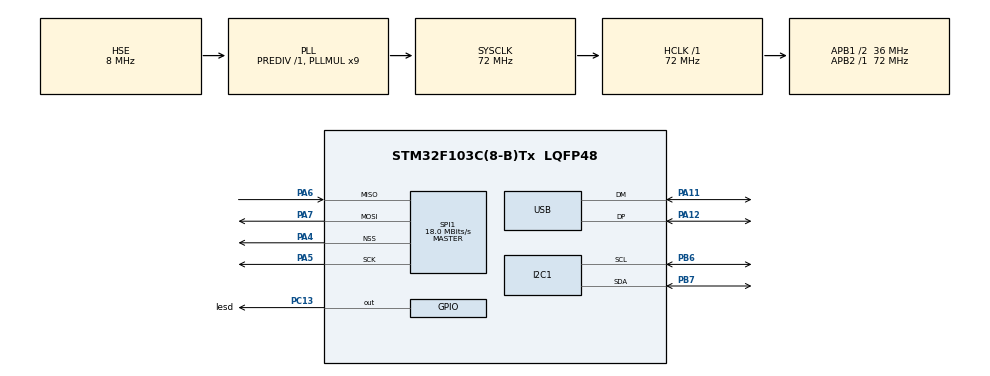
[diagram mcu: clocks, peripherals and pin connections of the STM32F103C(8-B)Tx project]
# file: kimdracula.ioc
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I2C1.DualAddressMode=I2C_DUALADDRESS_DISABLE
I2C1.GeneralCallMode=I2C_GENERALCALL_ENABLE
I2C1.I2C_Mode=I2C_Standard
I2C1.OwnAddress=79
Mcu.Family=STM32F1
Mcu.Name=STM32F103C(8-B)Tx
Mcu.Package=LQFP48
NVIC.PriorityGroup=NVIC_PRIORITYGROUP_4
NVIC.USB_LP_CAN1_RX0_IRQn=true\:0\:0\:false\:false\:true\:false\:true
PA11.Mode=Device
PA11.Signal=USB_DM
PA12.Mode=Device
PA12.Signal=USB_DP
PA4.Mode=NSS_Signal_Hard_Output
PA4.Signal=SPI1_NSS
PA5.Mode=Full_Duplex_Master
PA5.Signal=SPI1_SCK
PA6.Mode=Full_Duplex_Master
PA6.Signal=SPI1_MISO
PA7.Mode=Full_Duplex_Master
PA7.Signal=SPI1_MOSI
PB6.Mode=I2C
PB6.Signal=I2C1_SCL
PB7.Mode=I2C
PB7.Signal=I2C1_SDA
PC13-TAMPER-RTC.GPIO_Label=lesd
PC13-TAMPER-RTC.PinState=GPIO_PIN_SET
PC13-TAMPER-RTC.Signal=GPIO_Output
PD0-OSC_IN.Mode=HSE-External-Oscillator
PD0-OSC_IN.Signal=RCC_OSC_IN
PD1-OSC_OUT.Mode=HSE-External-Oscillator
PD1-OSC_OUT.Signal=RCC_OSC_OUT
ProjectManager.HeapSize=0x200
ProjectManager.StackSize=0x400
ProjectManager.TargetToolchain=SW4STM32
RCC.AHBFreq_Value=72000000
RCC.APB1CLKDivider=RCC_HCLK_DIV2
RCC.APB1Freq_Value=36000000
RCC.APB1TimFreq_Value=72000000
RCC.APB2Freq_Value=72000000
RCC.APB2TimFreq_Value=72000000
RCC.HCLKFreq_Value=72000000
RCC.PLLMUL=RCC_PLL_MUL9
RCC.SYSCLKFreq_VALUE=72000000
RCC.SYSCLKSource=RCC_SYSCLKSOURCE_PLLCLK
RCC.USBFreq_Value=48000000
RCC.USBPrescaler=RCC_USBCLKSOURCE_PLL_DIV1_5
SPI1.BaudRatePrescaler=SPI_BAUDRATEPRESCALER_4
SPI1.CalculateBaudRate=18.0 MBits/s
SPI1.Direction=SPI_DIRECTION_2LINES
SPI1.Mode=SPI_MODE_MASTER
SPI1.VirtualNSS=VM_NSSHARD
SPI1.VirtualType=VM_MASTER
USB_DEVICE.CLASS_NAME_FS=CDC
USB_DEVICE.VirtualMode=Cdc
USB_DEVICE.VirtualModeFS=Cdc_FS
VP_SYS_VS_ND.Mode=No_Debug
VP_USB_DEVICE_VS_USB_DEVICE_CDC_FS.Mode=CDC_FS
board=custom

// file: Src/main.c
/* USER CODE BEGIN Header */
/**
  ******************************************************************************
  * @file           : main.c
  * @brief          : Main program body
  ******************************************************************************
  * @attention
  *
  * <h2><center>&copy; Copyright (c) 2019 STMicroelectronics.
  * All rights reserved.</center></h2>
  *
  * This software component is licensed by ST under Ultimate Liberty license
  * SLA0044, the "License"; You may not use this file except in compliance with
  * the License. You may obtain a copy of the License at:
  *                             www.st.com/SLA0044
  *
  ******************************************************************************
  */
/* USER CODE END Header */

#include "main.h"
#include "usb_device.h"
#include "stm32f1xx.h"
#include "stm32f1xx_hal_rcc.h"
#include "stm32f1xx_hal_i2c.h"
#include <math.h>
#include <stdbool.h>
#include <stdio.h>

#define I2C1_SCL_Pin GPIO_PIN_6
#define I2C1_SCL_GPIO_Port GPIOB
#define I2C1_SDA_Pin GPIO_PIN_7
#define I2C1_SDA_GPIO_Port GPIOB

/* Hardware Addresses */
#define MPU6050			0x69<<1
#define BMP180			0xEF

/* Register Maps */
	//MPU6050
#define SYSTEM_CONFIG	0x1A

#define TEMP_OUT_H		0x41
#define TEMP_OUT_L		0x42

#define ACCEL_CONFIG	0x1c

#define ACCEL_XOUT_H	0x3b
#define ACCEL_XOUT_L	0x3c

#define ACCEL_YOUT_H	0x3d
#define ACCEL_YOUT_L	0x3e

#define ACCEL_ZOUT_H	0x3f
#define ACCEL_ZOUT_L	0x40

#define GYROS_CONFIG	0x1b

#define GYROS_XOUT_H	0x43
#define GYROS_XOUT_L	0x44

#define GYROS_YOUT_H	0x45
#define GYROS_YOUT_L	0x46

#define GYROS_ZOUT_H	0x47
#define GYROS_ZOUT_L	0x48

	//BMP180

I2C_HandleTypeDef hi2c1;

SPI_HandleTypeDef hspi1;

/* USER CODE BEGIN PV */
uint8_t status = 0;
uint8_t rxbuf_i2c;
uint8_t txbuf_i2c[2];

/* USER CODE END PV */

void SystemClock_Config(void);
static void MX_GPIO_Init(void);
static void MX_I2C1_Init(void);
static void MX_SPI1_Init(void);
//void spit_i2c(void);
//void send_linebreak(void);
//uint8_t CDC_Transmit_FS(uint8_t* Buf, uint16_t Len);

/*
void send_linebreak(void){
	char linebreak[] = ";\n\r";
	CDC_Transmit_FS(linebreak, strlen(linebreak));
}
void spit_i2c(void){

}
*/
// TODO: IMPLEMENTAR DMA

int main(void)
{

  /* MCU Configuration--------------------------------------------------------*/

  /* Reset of all peripherals, Initializes the Flash interface and the Systick. */
  HAL_Init();

  /* Configure the system clock */
  SystemClock_Config();

  /* Initialize all configured peripherals */
  MX_GPIO_Init();
  MX_USB_DEVICE_Init();
  MX_I2C1_Init();
  MX_SPI1_Init();
  // HAL_I2C_ModeType
  uint8_t rx;
  /* Infinite loop */
  while (1){
	  HAL_GPIO_TogglePin(GPIOC, GPIO_PIN_13);
	  HAL_Delay(3000);

  }
  /* USER CODE END 3 */
}

void SystemClock_Config(void)
{
  RCC_OscInitTypeDef RCC_OscInitStruct = {0};
  RCC_ClkInitTypeDef RCC_ClkInitStruct = {0};
  RCC_PeriphCLKInitTypeDef PeriphClkInit = {0};

  /** Initializes the CPU, AHB and APB busses clocks
  */
  RCC_OscInitStruct.OscillatorType = RCC_OSCILLATORTYPE_HSE;
  RCC_OscInitStruct.HSEState = RCC_HSE_ON;
  RCC_OscInitStruct.HSEPredivValue = RCC_HSE_PREDIV_DIV1;
  RCC_OscInitStruct.HSIState = RCC_HSI_ON;
  RCC_OscInitStruct.PLL.PLLState = RCC_PLL_ON;
  RCC_OscInitStruct.PLL.PLLSource = RCC_PLLSOURCE_HSE;
  RCC_OscInitStruct.PLL.PLLMUL = RCC_PLL_MUL9;
  if (HAL_RCC_OscConfig(&RCC_OscInitStruct) != HAL_OK)
  {
    Error_Handler();
  }
  /** Initializes the CPU, AHB and APB busses clocks
  */
  RCC_ClkInitStruct.ClockType = RCC_CLOCKTYPE_HCLK|RCC_CLOCKTYPE_SYSCLK
                              |RCC_CLOCKTYPE_PCLK1|RCC_CLOCKTYPE_PCLK2;
  RCC_ClkInitStruct.SYSCLKSource = RCC_SYSCLKSOURCE_PLLCLK;
  RCC_ClkInitStruct.AHBCLKDivider = RCC_SYSCLK_DIV1;
  RCC_ClkInitStruct.APB1CLKDivider = RCC_HCLK_DIV2;
  RCC_ClkInitStruct.APB2CLKDivider = RCC_HCLK_DIV1;

  if (HAL_RCC_ClockConfig(&RCC_ClkInitStruct, FLASH_LATENCY_2) != HAL_OK)
  {
    Error_Handler();
  }
  PeriphClkInit.PeriphClockSelection = RCC_PERIPHCLK_USB;
  PeriphClkInit.UsbClockSelection = RCC_USBCLKSOURCE_PLL_DIV1_5;
  if (HAL_RCCEx_PeriphCLKConfig(&PeriphClkInit) != HAL_OK)
  {
    Error_Handler();
  }
}

static void MX_I2C1_Init(void)
{

  hi2c1.Instance = I2C1;
  hi2c1.Init.ClockSpeed = 100000;
  hi2c1.Init.DutyCycle = I2C_DUTYCYCLE_2;
  hi2c1.Init.OwnAddress1 = 0;
  hi2c1.Init.AddressingMode = I2C_ADDRESSINGMODE_7BIT;
  hi2c1.Init.DualAddressMode = I2C_DUALADDRESS_DISABLE;
  hi2c1.Init.OwnAddress2 = 0;
  hi2c1.Init.GeneralCallMode = I2C_GENERALCALL_DISABLE;
  hi2c1.Init.NoStretchMode = I2C_NOSTRETCH_DISABLE;

  if (HAL_I2C_Init(&hi2c1) != HAL_OK)
  {
    Error_Handler();
  }

}

static void MX_SPI1_Init(void)
{

  /* SPI1 parameter configuration*/
  hspi1.Instance = SPI1;
  hspi1.Init.Mode = SPI_MODE_MASTER;
  hspi1.Init.Direction = SPI_DIRECTION_2LINES;
  hspi1.Init.DataSize = SPI_DATASIZE_8BIT;
  hspi1.Init.CLKPolarity = SPI_POLARITY_LOW;
  hspi1.Init.CLKPhase = SPI_PHASE_1EDGE;
  hspi1.Init.NSS = SPI_NSS_HARD_OUTPUT;
  hspi1.Init.BaudRatePrescaler = SPI_BAUDRATEPRESCALER_4;
  hspi1.Init.FirstBit = SPI_FIRSTBIT_MSB;
  hspi1.Init.TIMode = SPI_TIMODE_DISABLE;
  hspi1.Init.CRCCalculation = SPI_CRCCALCULATION_DISABLE;
  hspi1.Init.CRCPolynomial = 10;
  if (HAL_SPI_Init(&hspi1) != HAL_OK)
  {
    Error_Handler();
  }

}

static void MX_GPIO_Init(void)
{
  GPIO_InitTypeDef GPIO_InitStruct = {0};

  /* GPIO Ports Clock Enable */
  __HAL_RCC_GPIOC_CLK_ENABLE();
  __HAL_RCC_GPIOD_CLK_ENABLE();
  __HAL_RCC_GPIOA_CLK_ENABLE();
  __HAL_RCC_GPIOB_CLK_ENABLE();

  /*Configure GPIO pin Output Level */
  HAL_GPIO_WritePin(lesd_GPIO_Port, lesd_Pin, GPIO_PIN_SET);

  /*Configure GPIO pin : lesd_Pin */
  GPIO_InitStruct.Pin = lesd_Pin;
  GPIO_InitStruct.Mode = GPIO_MODE_OUTPUT_PP;
  GPIO_InitStruct.Pull = GPIO_NOPULL;
  GPIO_InitStruct.Speed = GPIO_SPEED_FREQ_LOW;
  HAL_GPIO_Init(lesd_GPIO_Port, &GPIO_InitStruct);

}

void Error_Handler(void)
{
}

/************************ (C) COPYRIGHT STMicroelectronics *****END OF FILE****/
